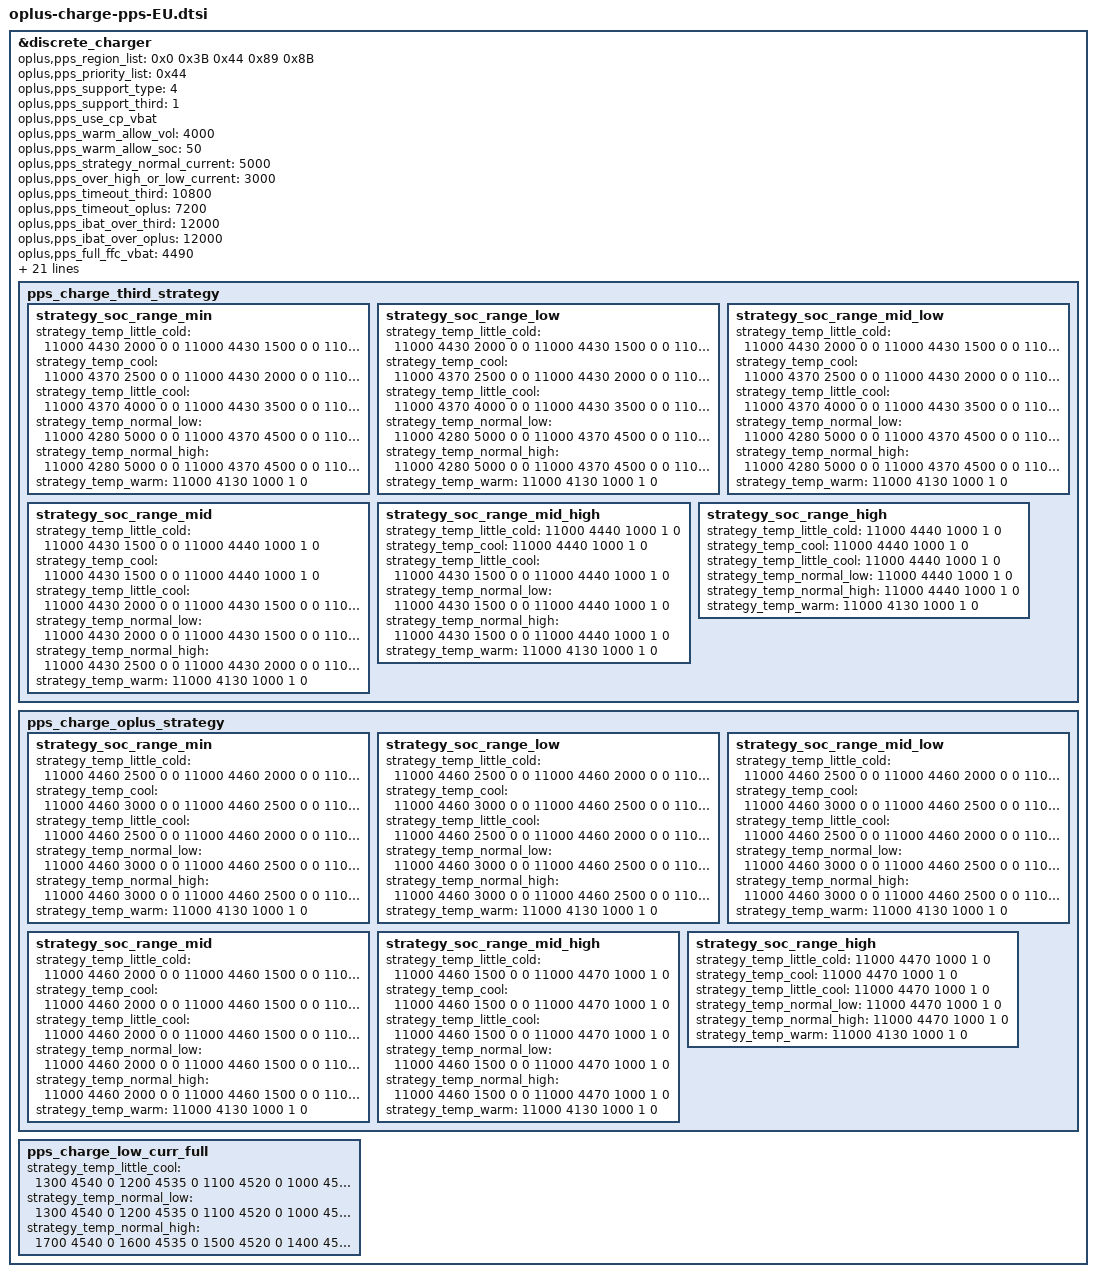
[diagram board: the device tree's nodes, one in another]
&discrete_charger {
	// 3rd PPS
	oplus,pps_region_list = <0x0 0x3B 0x44 0x89 0x8B>;
	oplus,pps_priority_list = <0x44>;
	oplus,pps_support_type = <4>;
	oplus,pps_support_third = <1>;
	oplus,pps_use_cp_vbat;
	oplus,pps_warm_allow_vol = <4000>;
	oplus,pps_warm_allow_soc = <50>;
	oplus,pps_strategy_normal_current = <5000>;//10A
	oplus,pps_over_high_or_low_current = <3000>;
	oplus,pps_timeout_third = <10800>;
	oplus,pps_timeout_oplus = <7200>;
	oplus,pps_ibat_over_third = <12000>;
	oplus,pps_ibat_over_oplus = <12000>;
	oplus,pps_full_ffc_vbat = <4490>;
	oplus,pps_full_cool_sw_vbat = <4440>;
	oplus,pps_full_normal_sw_vbat = <4440>;
	oplus,pps_full_normal_hw_vbat = <4450>;
	oplus,pps_full_warm_vbat = <4130>;
	oplus,pps_full_cool_sw_vbat_third = <4440>;
	oplus,pps_full_normal_sw_vbat_third = <4440>;
	oplus,pps_full_normal_hw_vbat_third = <4450>; //charging limit voltage + 10
	oplus,pps_r_default = <95 45 10 45 20 20 20>;
	oplus,pps_rmos_mohm = <5>;
	oplus,pps_exit_ms = <500>;
	oplus,pps_r_limit = <260 200 140 90 40>;
	oplus,pps_strategy_batt_high_temp = <410 420 430 400 410 420>;
	oplus,pps_strategy_high_current = <3000 2000 2000 3000 3000 2000>;
	oplus,pps_charge_strategy_soc = <0 15 35 50 75 85 90>;
	oplus,pps_charge_strategy_temp = <0 50 120 160 350 440 510>;
	oplus,pps_low_curr_full_strategy_temp = <120 160 350 440>;

	pps_charge_third_strategy {
		// 0 ~ 15
		strategy_soc_range_min {
			strategy_temp_little_cold =	<11000 4430 2000 0 0
							11000 4430 1500 0 0
							11000 4440 1000 1 0>;
			strategy_temp_cool =		<11000 4370 2500 0 0
							11000 4430 2000 0 0
							11000 4430 1500 0 0
							11000 4440 1000 1 0>;
			strategy_temp_little_cool =	<11000 4370 4000 0 0
							11000 4430 3500 0 0
							11000 4430 3000 0 0
							11000 4430 2500 0 0
							11000 4430 2000 0 0
							11000 4430 1500 0 0
							11000 4440 1000 1 0>;
			strategy_temp_normal_low =	<11000 4280 5000 0 0
							11000 4370 4500 0 0
							11000 4370 4000 0 0
							11000 4430 3500 0 0
							11000 4430 3000 0 0
							11000 4430 2500 0 0
							11000 4430 2000 0 0
							11000 4430 1500 0 0
							11000 4440 1000 1 0>;
			strategy_temp_normal_high =	<11000 4280 5000 0 0
							11000 4370 4500 0 0
							11000 4370 4000 0 0
							11000 4430 3500 0 0
							11000 4430 3000 0 0
							11000 4430 2500 0 0
							11000 4430 2000 0 0
							11000 4430 1500 0 0
							11000 4440 1000 1 0>;
			strategy_temp_warm =		<11000 4130 1000 1 0>;
		};
		// 15 ~ 35
		strategy_soc_range_low {
			strategy_temp_little_cold =	<11000 4430 2000 0 0
							11000 4430 1500 0 0
							11000 4440 1000 1 0>;
			strategy_temp_cool =		<11000 4370 2500 0 0
							11000 4430 2000 0 0
							11000 4430 1500 0 0
							11000 4440 1000 1 0>;
			strategy_temp_little_cool =	<11000 4370 4000 0 0
							11000 4430 3500 0 0
							11000 4430 3000 0 0
							11000 4430 2500 0 0
							11000 4430 2000 0 0
							11000 4430 1500 0 0
							11000 4440 1000 1 0>;
			strategy_temp_normal_low =	<11000 4280 5000 0 0
							11000 4370 4500 0 0
							11000 4370 4000 0 0
							11000 4430 3500 0 0
							11000 4430 3000 0 0
							11000 4430 2500 0 0
							11000 4430 2000 0 0
							11000 4430 1500 0 0
							11000 4440 1000 1 0>;
			strategy_temp_normal_high =	<11000 4280 5000 0 0
							11000 4370 4500 0 0
							11000 4370 4000 0 0
							11000 4430 3500 0 0
							11000 4430 3000 0 0
							11000 4430 2500 0 0
							11000 4430 2000 0 0
							11000 4430 1500 0 0
							11000 4440 1000 1 0>;
			strategy_temp_warm =		<11000 4130 1000 1 0>;
		};
		// 35 ~ 50
		strategy_soc_range_mid_low {
			strategy_temp_little_cold =	<11000 4430 2000 0 0
							11000 4430 1500 0 0
							11000 4440 1000 1 0>;
			strategy_temp_cool =		<11000 4370 2500 0 0
							11000 4430 2000 0 0
							11000 4430 1500 0 0
							11000 4440 1000 1 0>;
			strategy_temp_little_cool =	<11000 4370 4000 0 0
							11000 4430 3500 0 0
							11000 4430 3000 0 0
							11000 4430 2500 0 0
							11000 4430 2000 0 0
							11000 4430 1500 0 0
							11000 4440 1000 1 0>;
			strategy_temp_normal_low =	<11000 4280 5000 0 0
							11000 4370 4500 0 0
							11000 4370 4000 0 0
							11000 4430 3500 0 0
							11000 4430 3000 0 0
							11000 4430 2500 0 0
							11000 4430 2000 0 0
							11000 4430 1500 0 0
							11000 4440 1000 1 0>;
			strategy_temp_normal_high =	<11000 4280 5000 0 0
							11000 4370 4500 0 0
							11000 4370 4000 0 0
							11000 4430 3500 0 0
							11000 4430 3000 0 0
							11000 4430 2500 0 0
							11000 4430 2000 0 0
							11000 4430 1500 0 0
							11000 4440 1000 1 0>;
			strategy_temp_warm =		<11000 4130 1000 1 0>;
		};
		// 50 ~ 75
		strategy_soc_range_mid {
			strategy_temp_little_cold =	<11000 4430 1500 0 0
							11000 4440 1000 1 0>;
			strategy_temp_cool =		<11000 4430 1500 0 0
							11000 4440 1000 1 0>;
			strategy_temp_little_cool =	<11000 4430 2000 0 0
							11000 4430 1500 0 0
							11000 4440 1000 1 0>;
			strategy_temp_normal_low =	<11000 4430 2000 0 0
							11000 4430 1500 0 0
							11000 4440 1000 1 0>;
			strategy_temp_normal_high =	<11000 4430 2500 0 0
							11000 4430 2000 0 0
							11000 4430 1500 0 0
							11000 4440 1000 1 0>;
			strategy_temp_warm =		<11000 4130 1000 1 0>;
		};
		// 75 ~ 85
		strategy_soc_range_mid_high {
			strategy_temp_little_cold =	<11000 4440 1000 1 0>;
			strategy_temp_cool =		<11000 4440 1000 1 0>;
			strategy_temp_little_cool =	<11000 4430 1500 0 0
							11000 4440 1000 1 0>;
			strategy_temp_normal_low =	<11000 4430 1500 0 0
							11000 4440 1000 1 0>;
			strategy_temp_normal_high =	<11000 4430 1500 0 0
							11000 4440 1000 1 0>;
			strategy_temp_warm =		<11000 4130 1000 1 0>;
		};
		// 85 ~ 90
		strategy_soc_range_high {
			strategy_temp_little_cold =	<11000 4440 1000 1 0>;
			strategy_temp_cool =		<11000 4440 1000 1 0>;
			strategy_temp_little_cool =	<11000 4440 1000 1 0>;
			strategy_temp_normal_low =	<11000 4440 1000 1 0>;
			strategy_temp_normal_high =	<11000 4440 1000 1 0>;
			strategy_temp_warm =		<11000 4130 1000 1 0>;
		};
	};
	pps_charge_oplus_strategy {
		// 0 ~ 15
		strategy_soc_range_min {
			strategy_temp_little_cold =	<11000 4460 2500 0 0
							11000 4460 2000 0 0
							11000 4460 1500 0 0
							11000 4470 1000 1 0>;
			strategy_temp_cool =	<11000 4460 3000 0 0
							11000 4460 2500 0 0
							11000 4460 2000 0 0
							11000 4460 1500 0 0
							11000 4470 1000 1 0>;
			strategy_temp_little_cool =	<11000 4460 2500 0 0
							11000 4460 2000 0 0
							11000 4460 1500 0 0
							11000 4470 1000 1 0>;
			strategy_temp_normal_low =	<11000 4460 3000 0 0
							11000 4460 2500 0 0
							11000 4460 2000 0 0
							11000 4460 1500 0 0
							11000 4470 1000 1 0>;
			strategy_temp_normal_high =	<11000 4460 3000 0 0
							11000 4460 2500 0 0
							11000 4460 2000 0 0
							11000 4460 1500 0 0
							11000 4470 1000 1 0>;
			strategy_temp_warm =		<11000 4130 1000 1 0>;
		};
		// 15 ~ 35
		strategy_soc_range_low {
			strategy_temp_little_cold =	<11000 4460 2500 0 0
							11000 4460 2000 0 0
							11000 4460 1500 0 0
							11000 4470 1000 1 0>;
			strategy_temp_cool =	<11000 4460 3000 0 0
							11000 4460 2500 0 0
							11000 4460 2000 0 0
							11000 4460 1500 0 0
							11000 4470 1000 1 0>;
			strategy_temp_little_cool =	<11000 4460 2500 0 0
							11000 4460 2000 0 0
							11000 4460 1500 0 0
							11000 4470 1000 1 0>;
			strategy_temp_normal_low =	<11000 4460 3000 0 0
							11000 4460 2500 0 0
							11000 4460 2000 0 0
							11000 4460 1500 0 0
							11000 4470 1000 1 0>;
			strategy_temp_normal_high =	<11000 4460 3000 0 0
							11000 4460 2500 0 0
							11000 4460 2000 0 0
							11000 4460 1500 0 0
							11000 4470 1000 1 0>;
			strategy_temp_warm =		<11000 4130 1000 1 0>;
		};
		// 35 ~ 50
		strategy_soc_range_mid_low {
			strategy_temp_little_cold =	<11000 4460 2500 0 0
							11000 4460 2000 0 0
							11000 4460 1500 0 0
							11000 4470 1000 1 0>;
			strategy_temp_cool =	<11000 4460 3000 0 0
							11000 4460 2500 0 0
							11000 4460 2000 0 0
							11000 4460 1500 0 0
							11000 4470 1000 1 0>;
			strategy_temp_little_cool =	<11000 4460 2500 0 0
							11000 4460 2000 0 0
							11000 4460 1500 0 0
							11000 4470 1000 1 0>;
			strategy_temp_normal_low =	<11000 4460 3000 0 0
							11000 4460 2500 0 0
							11000 4460 2000 0 0
							11000 4460 1500 0 0
							11000 4470 1000 1 0>;
			strategy_temp_normal_high =	<11000 4460 3000 0 0
							11000 4460 2500 0 0
							11000 4460 2000 0 0
							11000 4460 1500 0 0
							11000 4470 1000 1 0>;
			strategy_temp_warm =		<11000 4130 1000 1 0>;
		};
		// 50 ~ 75
		strategy_soc_range_mid {
			strategy_temp_little_cold =	<11000 4460 2000 0 0
							11000 4460 1500 0 0
							11000 4470 1000 1 0>;
			strategy_temp_cool =		<11000 4460 2000 0 0
							11000 4460 1500 0 0
							11000 4470 1000 1 0>;
			strategy_temp_little_cool =	<11000 4460 2000 0 0
							11000 4460 1500 0 0
							11000 4470 1000 1 0>;
			strategy_temp_normal_low =	<11000 4460 2000 0 0
							11000 4460 1500 0 0
							11000 4470 1000 1 0>;
			strategy_temp_normal_high =	<11000 4460 2000 0 0
							11000 4460 1500 0 0
							11000 4470 1000 1 0>;
			strategy_temp_warm =		<11000 4130 1000 1 0>;
		};
		// 75 ~ 85
		strategy_soc_range_mid_high {
			strategy_temp_little_cold =	<11000 4460 1500 0 0
							11000 4470 1000 1 0>;
			strategy_temp_cool =		<11000 4460 1500 0 0
							11000 4470 1000 1 0>;
			strategy_temp_little_cool =	<11000 4460 1500 0 0
							11000 4470 1000 1 0>;
			strategy_temp_normal_low =	<11000 4460 1500 0 0
							11000 4470 1000 1 0>;
			strategy_temp_normal_high =	<11000 4460 1500 0 0
							11000 4470 1000 1 0>;
			strategy_temp_warm =		<11000 4130 1000 1 0>;
		};
		// 85 ~ 90
		strategy_soc_range_high {
			strategy_temp_little_cold =	<11000 4470 1000 1 0>;
			strategy_temp_cool =		<11000 4470 1000 1 0>;
			strategy_temp_little_cool =	<11000 4470 1000 1 0>;
			strategy_temp_normal_low =	<11000 4470 1000 1 0>;
			strategy_temp_normal_high =	<11000 4470 1000 1 0>;
			strategy_temp_warm =		<11000 4130 1000 1 0>;
		};
	};
	pps_charge_low_curr_full {
		strategy_temp_little_cool = 	<1300  4540 0
						1200  4535 0
						1100  4520 0
						1000  4510 0
						950   4500 1>;
		strategy_temp_normal_low = 	<1300  4540 0
						1200  4535 0
						1100  4520 0
						1000  4510 0
						950   4500 1>;
		strategy_temp_normal_high = 	<1700  4540 0
						1600  4535 0
						1500  4520 0
						1400  4510 0
						1300  4500 1>;
	};
};
